# M471 register map
File version: 1.0
Registers are 32-bit, read-write, reset 0x0 unless marked. A register's access mark holds for its fields unless they carry their own. Offsets are from the block's base; [hi:lo] are bit positions; 'fields as' and 'values as' point back to an identical list.

## SPI0 — SPI Register Map
Base 0x40061000
Same registers: SPI1 0x40062000
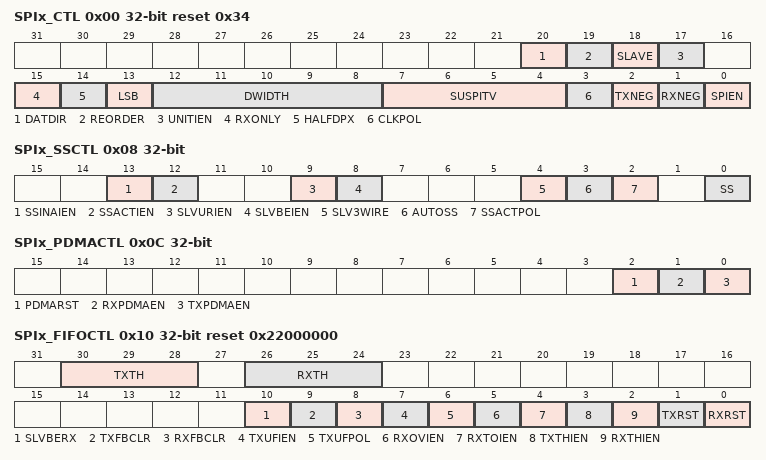
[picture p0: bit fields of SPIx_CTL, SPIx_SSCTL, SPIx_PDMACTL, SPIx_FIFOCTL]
0x00 SPIx_CTL reset 0x34 — SPI Control Register
  [20] DATDIR — Data Port Direction Control. This bit is used to select the data input/output direction in half-duplex transfer and Dual/Quad transfer
    0=SPI data is input direction; 1=SPI data is output direction
  [19] REORDER — Byte Reorder Function Enable Bit. Note: Byte Reorder function is only available if DWIDTH is defined as 16, 24, and 32 bits.
    0=Byte Reorder function Disabled; 1=Byte Reorder function Enabled. A byte suspend interval will be inserted among each byte. The period of the byte suspend interval depends on the setting of SUSPITV
  [18] SLAVE — Slave Mode Control
    0=Master mode; 1=Slave mode
  [17] UNITIEN — Unit Transfer Interrupt Enable Bit
    0=SPI unit transfer interrupt Disabled; 1=SPI unit transfer interrupt Enabled
  [15] RXONLY — Receive-only Mode Enable Bit. This bit field is only available in Master mode. In receive-only mode, SPI Master will generate SPI bus clock continuously for receiving data bit from SPI slave device and assert the BUSY status.
    0=Receive-only mode Disabled; 1=Receive-only mode Enabled
  [14] HALFDPX — SPI Half-duplex Transfer Enable Bit. This bit is used to select full-duplex or half-duplex for SPI transfer. The bit field DATDIR (SPIx_CTL[20]) can be used to set the data direction in half-duplex transfer.
    0=SPI operates in full-duplex transfer; 1=SPI operates in half-duplex transfer
  [13] LSB — Send LSB First
    0=The MSB, which bit of transmit/receive register depends on the setting of DWIDTH, is transmitted/received first; 1=The LSB, bit 0 of the SPI TX register, is sent first to the SPI data output pin, and the first bit received from the SPI data input pin will be put in the LSB position of the RX register (bit 0 of SPI_RX)
  [12:8] DWIDTH — Data Width. This field specifies how many bits can be transmitted / received in one transaction. The minimum bit length is 4 bits and can up to 32 bits. Note: This bit field will decide the depth of TX/RX FIFO configuration in SPI mode. Therefore, changing this bit field will clear TX/RX FIFO by hardware automatically.
  [7:4] SUSPITV — Suspend Interval. The four bits provide configurable suspend interval between two successive transmit/receive transaction in a transfer. The definition of the suspend interval is the interval between the last clock edge of the preceding transaction word and the first clock edge of the following transaction word. The default value is 0x3. The period of the suspend interval is obtained according to the following equation. (SUSPITV + 0.5) * period of SPICLK clock cycle. Example: Note: Master Mode only.
  [3] CLKPOL — Clock Polarity
    0=SPI bus clock is idle low; 1=SPI bus clock is idle high
  [2] TXNEG — Transmit on Negative Edge
    0=Transmitted data output signal is changed on the rising edge of SPI bus clock; 1=Transmitted data output signal is changed on the falling edge of SPI bus clock
  [1] RXNEG — Receive on Negative Edge
    0=Received data input signal is latched on the rising edge of SPI bus clock; 1=Received data input signal is latched on the falling edge of SPI bus clock
  [0] SPIEN — SPI Transfer Control Enable Bit. In Master mode, the transfer will start when there is data in the FIFO buffer after this bit is set to 1. In Slave mode, this device is ready to receive data when this bit is set to 1. Note: Before changing the configurations of SPIx_CTL, SPIx_CLKDIV, SPIx_SSCTL and SPIx_FIFOCTL registers, user shall clear the SPIEN (SPIx_CTL[0]) and confirm the SPIENSTS (SPIx_STATUS[15]) is 0.
    0=Transfer control Disabled; 1=Transfer control Enabled
0x04 SPIx_CLKDIV — SPI Clock Divider Register
  [8:0] DIVIDER — Clock Divider. The value in this field is the frequency divider for generating the peripheral clock, fspi_eclk, and the SPI bus clock of SPI Master. The frequency is obtained according to the following equation. where is the peripheral clock source, which is defined in the clock control register, CLK_CLKSEL2. Note 1: Not supported in I2S mode. Note 2: The time interval must be larger than or equal to 8 peripheral clock cycles between releasing SPI IP software reset and setting this clock divider register.
0x08 SPIx_SSCTL — SPI Slave Select Control Register
  [13] SSINAIEN — Slave Select Inactive Interrupt Enable Bit
    0=Slave select inactive interrupt Disabled; 1=Slave select inactive interrupt Enabled
  [12] SSACTIEN — Slave Select Active Interrupt Enable Bit
    0=Slave select active interrupt Disabled; 1=Slave select active interrupt Enabled
  [9] SLVURIEN — Slave Mode TX Under Run Interrupt Enable Bit
    0=Slave mode TX under run interrupt Disabled; 1=Slave mode TX under run interrupt Enabled
  [8] SLVBEIEN — Slave Mode Bit Count Error Interrupt Enable Bit
    0=Slave mode bit count error interrupt Disabled; 1=Slave mode bit count error interrupt Enabled
  [4] SLV3WIRE — Slave 3-wire Mode Enable Bit. In Slave 3-wire mode, the SPI controller can work with 3-wire interface including SPIx_CLK, SPIx_MISO and SPIx_MOSI pins. Note 1: The value of this register equals to control register SLAVE (SPIx_I2SCTL[8]) when I2S mode is enabled. Note 2: SPI Slave Mode only.
    0=4-wire bi-direction interface; 1=3-wire bi-direction interface
  [3] AUTOSS — Automatic Slave Selection Function Enable Bit. Note: Master Mode only.
    0=Automatic slave selection function Disabled. Slave selection signal will be asserted/de-asserted according to SS (SPIx_SSCTL[0]); 1=Automatic slave selection function Enabled
  [2] SSACTPOL — Slave Selection Active Polarity. This bit defines the active polarity of slave selection signal (SPIx_SS).
    0=The slave selection signal SPIx_SS is active low; 1=The slave selection signal SPIx_SS is active high
  [0] SS — Slave Selection Control. If AUTOSS bit is cleared to 0, Note: Master Mode only. . Note: It is Master Only. . Note: It is Master Only.
    0=set the SPIx_SS line to inactive state. Keep the SPIx_SS line at inactive state; 1=set the SPIx_SS line to active state. SPIx_SS line will be automatically driven to active state for the duration of data transfer, and will be driven to inactive state for the rest of the time. The active state of SPIx_SS is specified in SSACTPOL (SPIx_SSCTL[2])
0x0C SPIx_PDMACTL — SPI PDMA Control Register
  [2] PDMARST — PDMA Reset
    0=No effect; 1=Reset the PDMA control logic of the SPI controller. This bit will be automatically cleared to 0
  [1] RXPDMAEN — Receive PDMA Enable Bit
    0=Receive PDMA function Disabled; 1=Receive PDMA function Enabled
  [0] TXPDMAEN — Transmit PDMA Enable Bit. Note1: In SPI Master mode with full duplex transfer, if both TX and RX PDMA functions are enabled, RX PDMA function cannot be enabled prior to TX PDMA function. User can enable TX PDMA function firstly or enable both functions simultaneously. Note2: In SPI Master mode with full duplex transfer, if both TX and RX PDMA functions are enabled, TX PDMA function cannot be disabled prior to RX PDMA function. User can disable RX PDMA function firstly or disable both functions simultaneously.
    0=Transmit PDMA function Disabled; 1=Transmit PDMA function Enabled
0x10 SPIx_FIFOCTL reset 0x22000000 — SPI FIFO Control Register
  [30:28] TXTH — Transmit FIFO Threshold. If the valid data count of the transmit FIFO buffer is less than or equal to the TXTH setting, the TXTHIF bit will be set to 1, else the TXTHIF bit will be cleared to 0. The MSB of this bit field is only meaningful while SPI mode 4~16 bits of data length.
  [26:24] RXTH — Receive FIFO Threshold. If the valid data count of the receive FIFO buffer is larger than the RXTH setting, the RXTHIF bit will be set to 1, else the RXTHIF bit will be cleared to 0. The MSB of this bit field is only meaningful while SPI mode 4~16 bits of data length.
  [10] SLVBERX — RX FIFO Write Data Enable Bit When Slave Mode Bit Count Error. Note: SPI Slave Mode only.
    0=Uncompleted RX data will be dropped from RX FIFO when bit count error event happen in SPI slave mode; 1=Uncompleted RX data will be written into RX FIFO when bit count error event happen in SPI slave mode. User can read SLVBENUM (SPIx_STATUS2[29:24]) to know that the effective bit number of uncompleted RX data when SPI slave bit count error happened
  [9] TXFBCLR — Transmit FIFO Buffer Clear. Note: The TX shift register will not be cleared.
    0=No effect; 1=Clear transmit FIFO pointer. The TXFULL bit will be cleared to 0 and the TXEMPTY bit will be set to 1. This bit will be cleared to 0 by hardware about 1 system clock after it is set to 1
  [8] RXFBCLR — Receive FIFO Buffer Clear. Note: The RX shift register will not be cleared.
    0=No effect; 1=Clear receive FIFO pointer. The RXFULL bit will be cleared to 0 and the RXEMPTY bit will be set to 1. This bit will be cleared to 0 by hardware about 1 system clock after it is set to 1
  [7] TXUFIEN — TX Underflow Interrupt Enable Bit. When TX underflow event occurs in Slave mode, TXUFIF (SPIx_STATUS[19]) will be set to 1. This bit is used to enable the TX underflow interrupt.
    0=Slave TX underflow interrupt Disabled; 1=Slave TX underflow interrupt Enabled
  [6] TXUFPOL — TX Underflow Data Polarity. Note 1: The TX underflow event occurs if there is no any data in TX FIFO when the slave selection signal is active. Note 2: This bit should be set as 0 in I2S mode. Note 3: When TX underflow event occurs, SPIx_MISO pin state will be determined by this setting even though TX FIFO is not empty afterward. Data stored in TX FIFO will be sent through SPIx_MISO pin in the next transfer frame.
    0=The SPI data out is keep 0 if there is TX underflow event in Slave mode; 1=The SPI data out is keep 1 if there is TX underflow event in Slave mode
  [5] RXOVIEN — Receive FIFO Overrun Interrupt Enable Bit
    0=Receive FIFO overrun interrupt Disabled; 1=Receive FIFO overrun interrupt Enabled
  [4] RXTOIEN — Slave Receive Time-out Interrupt Enable Bit
    0=Receive time-out interrupt Disabled; 1=Receive time-out interrupt Enabled
  [3] TXTHIEN — Transmit FIFO Threshold Interrupt Enable Bit
    0=TX FIFO threshold interrupt Disabled; 1=TX FIFO threshold interrupt Enabled
  [2] RXTHIEN — Receive FIFO Threshold Interrupt Enable Bit
    0=RX FIFO threshold interrupt Disabled; 1=RX FIFO threshold interrupt Enabled
  [1] TXRST — Transmit Reset. Note: If TX underflow event occurs in SPI Slave mode, this bit can be used to make SPI return to idle state.
    0=No effect; 1=Reset transmit FIFO pointer and transmit circuit. The TXFULL bit will be cleared to 0 and the TXEMPTY bit will be set to 1. This bit will be cleared to 0 by hardware about 3 system clock cycles + 2 peripheral clock cycles after it is set to 1. User can read TXRXRST (SPIx_STATUS[23]) to check if reset is accomplished or not
  [0] RXRST — Receive Reset
    0=No effect; 1=Reset receive FIFO pointer and receive circuit. The RXFULL bit will be cleared to 0 and the RXEMPTY bit will be set to 1. This bit will be cleared to 0 by hardware about 3 system clock cycles + 2 peripheral clock cycles after it is set to 1. User can read TXRXRST (SPIx_STATUS[23]) to check if reset is accomplished or not
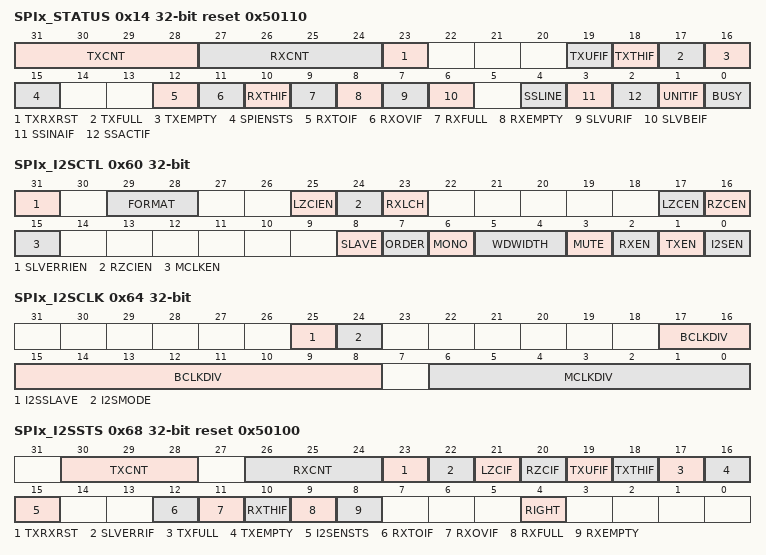
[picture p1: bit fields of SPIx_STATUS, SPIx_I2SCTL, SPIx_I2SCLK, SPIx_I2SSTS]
0x14 SPIx_STATUS reset 0x50110 — SPI Status Register
  [31:28] TXCNT ro — Transmit FIFO Data Count (Read Only). This bit field indicates the valid data count of transmit FIFO buffer.
  [27:24] RXCNT ro — Receive FIFO Data Count (Read Only). This bit field indicates the valid data count of receive FIFO buffer.
  [23] TXRXRST ro — TX or RX Reset Status (Read Only). Note: Both the reset operations of TXRST and RXRST need 3 system clock cycles + 2 peripheral clock cycles. User can check the status of this bit to monitor the reset function is doing or done.
    0=The reset function of TXRST or RXRST is done; 1=Doing the reset function of TXRST or RXRST
  [19] TXUFIF — TX Underflow Interrupt Flag. When the TX underflow event occurs, this bit will be set to 1, the state of data output pin depends on the setting of TXUFPOL. Note 1: This bit will be cleared by writing 1 to it. Note 2: If reset slave's transmission circuit when slave selection signal is active, this flag will be set to 1 after 2 peripheral clock cycles + 3 system clock cycles since the reset operation is done.
    0=No effect; 1=No data in Transmit FIFO and TX shift register when the slave selection signal is active
  [18] TXTHIF ro — Transmit FIFO Threshold Interrupt Flag (Read Only)
    0=The valid data count within the transmit FIFO buffer is larger than the setting value of TXTH; 1=The valid data count within the transmit FIFO buffer is less than or equal to the setting value of TXTH
  [17] TXFULL ro — Transmit FIFO Buffer Full Indicator (Read Only)
    0=Transmit FIFO buffer is not full; 1=Transmit FIFO buffer is full
  [16] TXEMPTY ro — Transmit FIFO Buffer Empty Indicator (Read Only)
    0=Transmit FIFO buffer is not empty; 1=Transmit FIFO buffer is empty
  [15] SPIENSTS ro — SPI Enable Status (Read Only). Note: The SPI peripheral clock is asynchronous with the system clock. In order to make sure the SPI control logic is disabled, this bit indicates the real status of SPI controller.
    0=SPI controller Disabled; 1=SPI controller Enabled
  [12] RXTOIF — Receive Time-out Interrupt Flag. Note: This bit will be cleared by writing 1 to it.
    0=No receive FIFO time-out event; 1=Receive FIFO buffer is not empty and no read operation on receive FIFO buffer over 64 SPI peripheral clock periods in Master mode or over 576 SPI peripheral clock periods in Slave mode. When the received FIFO buffer is read by software, the time-out status will be cleared automatically
  [11] RXOVIF — Receive FIFO Overrun Interrupt Flag. When the receive FIFO buffer is full, the follow-up data will be dropped and this bit will be set to 1. Note: This bit will be cleared by writing 1 to it.
    0=No FIFO is overrun; 1=Receive FIFO is overrun
  [10] RXTHIF ro — Receive FIFO Threshold Interrupt Flag (Read Only)
    0=The valid data count within the receive FIFO buffer is smaller than or equal to the setting value of RXTH; 1=The valid data count within the receive FIFO buffer is larger than the setting value of RXTH
  [9] RXFULL ro — Receive FIFO Buffer Full Indicator (Read Only)
    0=Receive FIFO buffer is not full; 1=Receive FIFO buffer is full
  [8] RXEMPTY ro — Receive FIFO Buffer Empty Indicator (Read Only)
    0=Receive FIFO buffer is not empty; 1=Receive FIFO buffer is empty
  [7] SLVURIF — Slave Mode TX Under Run Interrupt Flag. In Slave mode, if TX underflow event occurs and the slave select line goes to inactive state, this interrupt flag will be set to 1. Note: This bit will be cleared by writing 1 to it.
    0=No Slave TX under run event; 1=Slave TX under run event occurred
  [6] SLVBEIF — Slave Mode Bit Count Error Interrupt Flag. In Slave mode, when the slave select line goes to inactive state, if bit counter is mismatch with DWIDTH, this interrupt flag will be set to 1. Note: If the slave select active but there is no any bus clock input, the SLVBEIF also active when the slave select goes to inactive state. This bit will be cleared by writing 1 to it.
    0=No Slave mode bit count error event; 1=Slave mode bit count error event occurred
  [4] SSLINE ro — Slave Select Line Bus Status (Read Only). Note: This bit is only available in Slave mode. If SSACTPOL (SPIx_SSCTL[2]) is set 0, and the SSLINE is 1, the SPI slave select is in inactive status.
    0=The slave select line status is 0; 1=The slave select line status is 1
  [3] SSINAIF — Slave Select Inactive Interrupt Flag. Note: Only available in Slave mode. This bit will be cleared by writing 1 to it.
    0=Slave select inactive interrupt was cleared or not occurred; 1=Slave select inactive interrupt event occurred
  [2] SSACTIF — Slave Select Active Interrupt Flag. Note: Only available in Slave mode. This bit will be cleared by writing 1 to it.
    0=Slave select active interrupt was cleared or not occurred; 1=Slave select active interrupt event occurred
  [1] UNITIF — Unit Transfer Interrupt Flag. Note: This bit will be cleared by writing 1 to it.
    0=No transaction has been finished since this bit was cleared to 0; 1=SPI controller has finished one unit transfer
  [0] BUSY ro — Busy Status (Read Only). Note: By applications, this SPI bus flag should be used with other status registers in SPIx_STATUS such as TXCNT, RXCNT, TXTHIF, TXFULL, TXEMPTY, RXTHIF, RXFULL, RXEMPTY, and UNITIF. Therefore the SPI transfer done events of TX/RX operations can be obtained at correct timing point.
    0=SPI controller is in idle state; 1=SPI controller is in busy state
0x18 SPIx_STATUS2 ro — SPI Status2 Register
  [29:24] SLVBENUM — Effective Bit Number of Uncompleted RX Data. This status register indicates that effective bit number of uncompleted RX data when SLVBERX (SPIx_FIFOCTL[10]) is enabled and RX bit count error event happen in SPI slave mode. This status register will be fixed to 0x0 when SLVBERX (SPIx_FIFOCTL[10]) is disabled. Note 1: This register will be cleared to 0x0 when user write 0x1 to SLVBEIF (SPIx_STATUS[6]). Note 2: SPI Slave Mode only.
0x20 SPIx_TX wo — SPI Data Transmit Register
  [31:0] TX — Data Transmit Register. The data transmit registers pass through the transmitted data into the 4-level transmit FIFO buffers. The number of valid bits depends on the setting of DWIDTH (SPIx_CTL[12:8]) in SPI mode or WDWIDTH (SPIx_I2SCTL[5:4]) in I2S mode. In SPI mode, if DWIDTH is set to 0x08, the bits TX[7:0] will be transmitted. If DWIDTH is set to 0x00, the SPI controller will perform a 32-bit transfer. In I2S mode, if WDWIDTH (SPIx_I2SCTL[5:4]) is set to 0x2, the data width of audio channel is 24-bit and corresponding to TX[23:0]. If WDWIDTH is set as 0x0, 0x1, or 0x3, all bits of this field are valid and referred to the data arrangement in I2S mode FIFO operation section. Note: In Master mode, SPI controller will start to transfer the SPI bus clock after 1 APB clock and 6 peripheral clock cycles after user writes to this register.
0x30 SPIx_RX ro — SPI Data Receive Register
  [31:0] RX — Data Receive Register (Read Only). There are 4-level FIFO buffers in this controller. The data receive register holds the data received from SPI data input pin. If the RXEMPTY (SPIx_STATUS[8] or SPIx_I2SSTS[8]) is not set to 1, the receive FIFO buffers can be accessed through software by reading this register.
0x60 SPIx_I2SCTL — I2S Control Register
  [31] SLVERRIEN — Bit Number Error Interrupt Enable Bit for Slave Mode. Interrupt occurs if this bit is set to 1 and bit number error event occurs.
    0=Interrupt Disabled; 1=Interrupt Enabled
  [29:28] FORMAT — Data Format Selection
    0=I2S data format; 1=MSB justified data format; 2=PCM mode A; 3=PCM mode B
  [25] LZCIEN — Left Channel Zero Cross Interrupt Enable Bit. Interrupt occurs if this bit is set to 1 and left channel zero cross event occurs.
    0=Interrupt Disabled; 1=Interrupt Enabled
  [24] RZCIEN — Right Channel Zero Cross Interrupt Enable Bit. Interrupt occurs if this bit is set to 1 and right channel zero cross event occurs.
    0=Interrupt Disabled; 1=Interrupt Enabled
  [23] RXLCH — Receive Left Channel Enable Bit
    0=Receive right channel data in Mono mode; 1=Receive left channel data in Mono mode
  [17] LZCEN — Left Channel Zero Cross Detection Enable Bit. If this bit is set to 1, when sign bits of the current left channel TX data and the next left channel TX data change or next TX shift data bits are all 0 then I2S TX output data of the left channel is 0 and LZCIF flag in SPIx_I2SSTS register is set to 1. This function is only available in transmit operation.
    0=Left channel zero cross detection Disabled; 1=Left channel zero cross detection Enabled
  [16] RZCEN — Right Channel Zero Cross Detection Enable Bit. If this bit is set to 1, when sign bits of the current right channel TX data and the next right channel TX data change or next TX shift data bits are all 0 then I2S TX output data of the right channel is 0 and RZCIF flag in SPIx_I2SSTS register is set to 1. This function is only available in transmit operation.
    0=Right channel zero cross detection Disabled; 1=Right channel zero cross detection Enabled
  [15] MCLKEN — Master Clock Enable Bit. If MCLKEN is set to 1, I2S controller will generate master clock on SPIx_I2SMCLK pin for external audio devices.
    0=Master clock Disabled; 1=Master clock Enabled
  [8] SLAVE — Slave Mode. I2S can operate as master or slave. For Master mode, I2Sx_BCLK and I2Sx_LRCLK pins are output mode and send bit clock from this chip to audio CODEC chip. In Slave mode, I2Sx_BCLK and I2Sx_LRCLK pins are input mode and I2Sx_BCLK and I2Sx_LRCLK signals are received from outer audio CODEC chip.
    0=Master mode; 1=Slave mode
  [7] ORDER — Stereo Data Order in FIFO
    0=Left channel data at high byte; 1=Left channel data at low byte
  [6] MONO — Monaural Data
    0=Data is stereo format; 1=Data is monaural format
  [5:4] WDWIDTH — Word Width
    0=data size is 8-bit; 1=data size is 16-bit; 2=data size is 24-bit; 3=data size is 32-bit
  [3] MUTE — Transmit Mute Enable Bit
    0=Transmit data is shifted from buffer; 1=Transmit channel zero
  [2] RXEN — Receive Enable Bit
    0=Data receive Disabled; 1=Data receive Enabled
  [1] TXEN — Transmit Enable Bit
    0=Data transmit Disabled; 1=Data transmit Enabled
  [0] I2SEN — I2S Controller Enable Bit. Note 1: If enabling this bit, I2Sx_BCLK will start to output in Master mode. Note 2: Before changing the configurations of SPIx_I2SCTL, SPIx_I2SCLK, and SPIx_FIFOCTL registers, user shall clear the I2SEN (SPIx_I2SCTL[0]) and confirm the I2SENSTS (SPIx_I2SSTS[15]) is 0.
    0=I2S mode Disabled; 1=I2S mode Enabled
0x64 SPIx_I2SCLK — I2S Clock Divider Control Register
  [25] I2SSLAVE — I2S Clock Divider Number Selection for I2S Slave Mode and I2S Master Mode. User sets I2SSLAVE to set frequency of peripheral clock of I2S master mode and I2S slave mode when BCLKDIV (SPIx_I2SCLK[17:8]) is set. I2SSLAVE needs to be set before I2SEN (SPIx_I2SCTL[0]) is enabled.
    0=The frequency of peripheral clock sets to I2S master mode; 1=The frequency of peripheral clock sets to I2S slave mode
  [24] I2SMODE — I2S Clock Divider Number Selection for I2S Mode and SPI Mode. User sets I2SMODE to set frequency of peripheral clock of I2S mode or SPI mode when BCLKDIV (SPIx_I2SCLK[17:8]) or DIVIDER (SPIx_CLKDIV[8:0]) are set. I2SMODE needs to be set before I2SEN (SPIx_I2SCTL[0]) or SPIEN (SPIx_CTL[0]) is enabled.
    0=The frequency of peripheral clock sets to SPI mode; 1=The frequency of peripheral clock sets to I2S mode
  [17:8] BCLKDIV — Bit Clock Divider. The I2S controller will generate bit clock in Master mode. The clock frequency of bit clock, fBCLK, is determined by the following expression: where is the frequency of I2S peripheral clock source, which is defined in the clock control register CLK_CLKSEL2. In I2S Slave mode, this field is used to define the frequency of peripheral clock and it's determined by . The peripheral clock frequency in I2S Slave mode must be equal to or faster than 6 times of input bit clock. Note: The time interval must be larger than or equal to 8 peripheral clock cycles between releasing SPI IP software reset and setting this clock divider register.
  [6:0] MCLKDIV — Master Clock Divider. If MCLKEN is set to 1, I2S controller will generate master clock for external audio devices. The frequency of master clock, fMCLK, is determined by the following expressions: where is the frequency of I2S peripheral clock source, which is defined in the clock control register CLK_CLKSEL2. In general, the master clock rate is 256 times sampling clock rate.
0x68 SPIx_I2SSTS reset 0x50100 — I2S Status Register
  [30:28] TXCNT ro — Transmit FIFO Data Count (Read Only). This bit field indicates the valid data count of transmit FIFO buffer.
  [26:24] RXCNT ro — Receive FIFO Data Count (Read Only). This bit field indicates the valid data count of receive FIFO buffer.
  [23] TXRXRST ro — TX or RX Reset Status (Read Only). Note: Both the reset operations of TXRST and RXRST need 3 system clock cycles + 2 peripheral clock cycles. User can check the status of this bit to monitor the reset function is doing or done.
    values as SPIx_STATUS.TXRXRST
  [22] SLVERRIF — Bit Number Error Interrupt Flag for Slave Mode. Note: This bit will be cleared by writing 1 to it.
    0=No bit number error event occurred; 1=Bit number error event occurred
  [21] LZCIF — Left Channel Zero Cross Interrupt Flag
    0=No zero cross event occurred on left channel; 1=Zero cross event occurred on left channel
  [20] RZCIF — Right Channel Zero Cross Interrupt Flag
    0=No zero cross event occurred on right channel; 1=Zero cross event occurred on right channel
  [19] TXUFIF — Transmit FIFO Underflow Interrupt Flag. When the transmit FIFO buffer is empty and there is no datum written into the FIFO buffer, if there is more bus clock input, this bit will be set to 1. Note: This bit will be cleared by writing 1 to it.
  [18] TXTHIF ro — Transmit FIFO Threshold Interrupt Flag (Read Only)
    values as SPIx_STATUS.TXTHIF
  [17] TXFULL ro — Transmit FIFO Buffer Full Indicator (Read Only)
    values as SPIx_STATUS.TXFULL
  [16] TXEMPTY ro — Transmit FIFO Buffer Empty Indicator (Read Only)
    values as SPIx_STATUS.TXEMPTY
  [15] I2SENSTS ro — I2S Enable Status (Read Only). Note: The SPI peripheral clock is asynchronous with the system clock. In order to make sure the SPI/I2S control logic is disabled, this bit indicates the real status of SPI/I2S control logic for user.
    0=SPI/I2S control logic Disabled; 1=SPI/I2S control logic Enabled
  [12] RXTOIF — Receive Time-out Interrupt Flag. Note: This bit will be cleared by writing 1 to it.
    0=No receive FIFO time-out event; 1=Receive FIFO buffer is not empty and no read operation on receive FIFO buffer over 64 SPI peripheral clock period in Master mode or over 576 SPI peripheral clock period in Slave mode. When the received FIFO buffer is read by software, the time-out status will be cleared automatically
  [11] RXOVIF — Receive FIFO Overrun Interrupt Flag. When the receive FIFO buffer is full, the follow-up data will be dropped and this bit will be set to 1. Note: This bit will be cleared by writing 1 to it.
  [10] RXTHIF ro — Receive FIFO Threshold Interrupt Flag (Read Only)
    values as SPIx_STATUS.RXTHIF
  [9] RXFULL ro — Receive FIFO Buffer Full Indicator (Read Only)
    values as SPIx_STATUS.RXFULL
  [8] RXEMPTY ro — Receive FIFO Buffer Empty Indicator (Read Only)
    values as SPIx_STATUS.RXEMPTY
  [4] RIGHT ro — Right Channel (Read Only). This bit indicates the current transmit data is belong to which channel.
    0=Left channel; 1=Right channel
